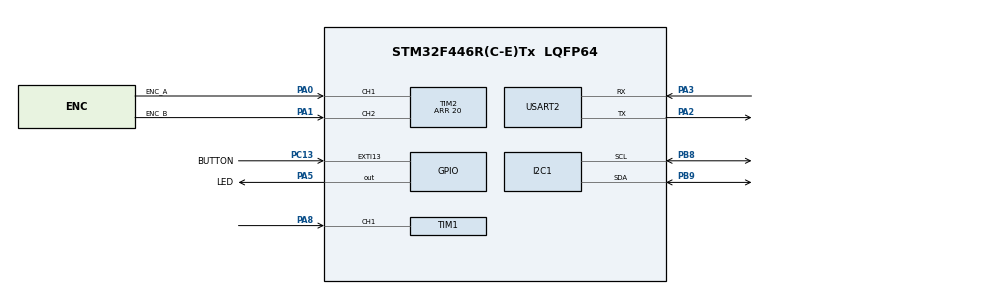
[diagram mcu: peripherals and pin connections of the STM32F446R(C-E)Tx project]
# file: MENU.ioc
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Mcu.Family=STM32F4
Mcu.Name=STM32F446R(C-E)Tx
Mcu.Package=LQFP64
NVIC.EXTI15_10_IRQn=true\:0\:0\:false\:false\:true\:true
NVIC.I2C1_ER_IRQn=true\:0\:0\:false\:false\:true\:true
NVIC.PriorityGroup=NVIC_PRIORITYGROUP_4
NVIC.TIM1_CC_IRQn=true\:0\:0\:false\:false\:true\:true
NVIC.TIM2_IRQn=true\:0\:0\:false\:false\:true\:true
PA0-WKUP.GPIO_Label=ENC_A
PA0-WKUP.GPIO_ModeDefaultPP=GPIO_MODE_AF_OD
PA0-WKUP.GPIO_PuPd=GPIO_PULLUP
PA0-WKUP.Signal=S_TIM2_CH1_ETR
PA1.GPIO_Label=ENC_B
PA1.GPIO_ModeDefaultPP=GPIO_MODE_AF_OD
PA1.GPIO_PuPd=GPIO_PULLUP
PA1.Signal=S_TIM2_CH2
PA13.Mode=Serial_Wire
PA13.Signal=SYS_JTMS-SWDIO
PA14.Mode=Serial_Wire
PA14.Signal=SYS_JTCK-SWCLK
PA2.Mode=Asynchronous
PA2.Signal=USART2_TX
PA3.Mode=Asynchronous
PA3.Signal=USART2_RX
PA5.GPIO_Label=LED
PA5.Signal=GPIO_Output
PA8.GPIO_ModeDefaultPP=GPIO_MODE_AF_PP
PA8.GPIO_PuPd=GPIO_PULLUP
PA8.Signal=S_TIM1_CH1
PB8.Mode=I2C
PB8.Signal=I2C1_SCL
PB9.Mode=I2C
PB9.Signal=I2C1_SDA
PC13.GPIO_Label=BUTTON
PC13.GPIO_ModeDefaultEXTI=GPIO_MODE_IT_RISING
PC13.GPIO_PuPd=GPIO_PULLUP
PC13.Signal=GPXTI13
ProjectManager.HeapSize=0x200
ProjectManager.StackSize=0x400
ProjectManager.TargetToolchain=TrueSTUDIO
RCC.AHBFreq_Value=16000000
RCC.APB1Freq_Value=16000000
RCC.APB1TimFreq_Value=16000000
RCC.APB2Freq_Value=16000000
RCC.APB2TimFreq_Value=16000000
RCC.CortexFreq_Value=16000000
RCC.HCLKFreq_Value=16000000
RCC.USBFreq_Value=96000000
RCC.VCOOutputFreq_Value=192000000
SH.S_TIM1_CH1.0=TIM1_CH1,Input_Capture1_from_TI1
SH.S_TIM1_CH1.1=TIM1_CH1,Input_Capture2_from_TI1
SH.S_TIM2_CH1_ETR.0=TIM2_CH1,Encoder_Interface
SH.S_TIM2_CH2.0=TIM2_CH2,Encoder_Interface
TIM1.Channel-Input_Capture1_from_TI1=TIM_CHANNEL_1
TIM1.Channel-Input_Capture2_from_TI1=TIM_CHANNEL_2
TIM1.ICFilter_CH1=15
TIM1.ICPolarity_CH2=TIM_INPUTCHANNELPOLARITY_FALLING
TIM1.Period=1999
TIM1.Prescaler=15999
TIM2.IC1Filter=15
TIM2.IC1Polarity=TIM_ICPOLARITY_FALLING
TIM2.IC2Filter=15
TIM2.IC2Polarity=TIM_ICPOLARITY_FALLING
TIM2.Period=20
USART2.VirtualMode=VM_ASYNC
board=custom

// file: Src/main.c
/**
  ******************************************************************************
  * @file           : main.c
  * @brief          : Main program body
  ******************************************************************************
  ** This notice applies to any and all portions of this file
  * that are not between comment pairs USER CODE BEGIN and
  * USER CODE END. Other portions of this file, whether
  * inserted by the user or by software development tools
  * are owned by their respective copyright owners.
  *
  * COPYRIGHT(c) 2019 STMicroelectronics
  *
  * Redistribution and use in source and binary forms, with or without modification,
  * are permitted provided that the following conditions are met:
  *   1. Redistributions of source code must retain the above copyright notice,
  *      this list of conditions and the following disclaimer.
  *   2. Redistributions in binary form must reproduce the above copyright notice,
  *      this list of conditions and the following disclaimer in the documentation
  *      and/or other materials provided with the distribution.
  *   3. Neither the name of STMicroelectronics nor the names of its contributors
  *      may be used to endorse or promote products derived from this software
  *      without specific prior written permission.
  *
  * THIS SOFTWARE IS PROVIDED BY THE COPYRIGHT HOLDERS AND CONTRIBUTORS "AS IS"
  * AND ANY EXPRESS OR IMPLIED WARRANTIES, INCLUDING, BUT NOT LIMITED TO, THE
  * IMPLIED WARRANTIES OF MERCHANTABILITY AND FITNESS FOR A PARTICULAR PURPOSE ARE
  * DISCLAIMED. IN NO EVENT SHALL THE COPYRIGHT HOLDER OR CONTRIBUTORS BE LIABLE
  * FOR ANY DIRECT, INDIRECT, INCIDENTAL, SPECIAL, EXEMPLARY, OR CONSEQUENTIAL
  * DAMAGES (INCLUDING, BUT NOT LIMITED TO, PROCUREMENT OF SUBSTITUTE GOODS OR
  * SERVICES; LOSS OF USE, DATA, OR PROFITS; OR BUSINESS INTERRUPTION) HOWEVER
  * CAUSED AND ON ANY THEORY OF LIABILITY, WHETHER IN CONTRACT, STRICT LIABILITY,
  * OR TORT (INCLUDING NEGLIGENCE OR OTHERWISE) ARISING IN ANY WAY OUT OF THE USE
  * OF THIS SOFTWARE, EVEN IF ADVISED OF THE POSSIBILITY OF SUCH DAMAGE.
  *
  ******************************************************************************
  */
#include "main.h"
#include "stm32f4xx_hal.h"
#include "i2c.h"
#include "tim.h"
#include "usart.h"
#include "gpio.h"

/* USER CODE BEGIN Includes */
#include "menu.h"
#include "AD9834.h"
#include "event.h"

#include "view_main_menu.h"
/* USER CODE END Includes */

typedef enum {
	opt_form = 0,
	opt_amplitude_val,
	opt_amplitude_pref,
	opt_frequency_val,
	opt_frequency_pref
}option_t;
/* USER CODE BEGIN PV */

option_t option = 4;
/* USER CODE END PV */

void SystemClock_Config(void);

int main(void)
{

  /* MCU Configuration----------------------------------------------------------*/

  /* Reset of all peripherals, Initializes the Flash interface and the Systick. */
  HAL_Init();

  /* Configure the system clock */
  SystemClock_Config();

  /* Initialize all configured peripherals */
  MX_GPIO_Init();
  MX_I2C1_Init();
  MX_USART2_UART_Init();
  MX_TIM1_Init();
  MX_TIM2_Init();
  /* USER CODE BEGIN 2 */
  HAL_TIM_Encoder_Start_IT(&htim2, TIM_CHANNEL_ALL);

  HAL_TIM_IC_Start_IT(&htim1, TIM_CHANNEL_1);
  HAL_TIM_IC_Start_IT(&htim1, TIM_CHANNEL_2);
  AD9834_init();
  menu_init();
  printf("perepherial has inited\n");

  /* USER CODE END 2 */

  /* Infinite loop */
  /* USER CODE BEGIN WHILE */
  while (1){
	  menu_execute();
	  HAL_Delay(100);
  }
  /* USER CODE END WHILE */

}

void SystemClock_Config(void)
{

  RCC_OscInitTypeDef RCC_OscInitStruct;
  RCC_ClkInitTypeDef RCC_ClkInitStruct;

    /**Configure the main internal regulator output voltage
    */
  __HAL_RCC_PWR_CLK_ENABLE();

  __HAL_PWR_VOLTAGESCALING_CONFIG(PWR_REGULATOR_VOLTAGE_SCALE3);

    /**Initializes the CPU, AHB and APB busses clocks
    */
  RCC_OscInitStruct.OscillatorType = RCC_OSCILLATORTYPE_HSI;
  RCC_OscInitStruct.HSIState = RCC_HSI_ON;
  RCC_OscInitStruct.HSICalibrationValue = 16;
  RCC_OscInitStruct.PLL.PLLState = RCC_PLL_NONE;
  if (HAL_RCC_OscConfig(&RCC_OscInitStruct) != HAL_OK)
  {
    _Error_Handler(__FILE__, __LINE__);
  }

    /**Initializes the CPU, AHB and APB busses clocks
    */
  RCC_ClkInitStruct.ClockType = RCC_CLOCKTYPE_HCLK|RCC_CLOCKTYPE_SYSCLK
                              |RCC_CLOCKTYPE_PCLK1|RCC_CLOCKTYPE_PCLK2;
  RCC_ClkInitStruct.SYSCLKSource = RCC_SYSCLKSOURCE_HSI;
  RCC_ClkInitStruct.AHBCLKDivider = RCC_SYSCLK_DIV1;
  RCC_ClkInitStruct.APB1CLKDivider = RCC_HCLK_DIV1;
  RCC_ClkInitStruct.APB2CLKDivider = RCC_HCLK_DIV1;

  if (HAL_RCC_ClockConfig(&RCC_ClkInitStruct, FLASH_LATENCY_0) != HAL_OK)
  {
    _Error_Handler(__FILE__, __LINE__);
  }

    /**Configure the Systick interrupt time
    */
  HAL_SYSTICK_Config(HAL_RCC_GetHCLKFreq()/1000);

    /**Configure the Systick
    */
  HAL_SYSTICK_CLKSourceConfig(SYSTICK_CLKSOURCE_HCLK);

  /* SysTick_IRQn interrupt configuration */
  HAL_NVIC_SetPriority(SysTick_IRQn, 0, 0);
}

void _Error_Handler(char *file, int line)
{
}

/************************ (C) COPYRIGHT STMicroelectronics *****END OF FILE****/
